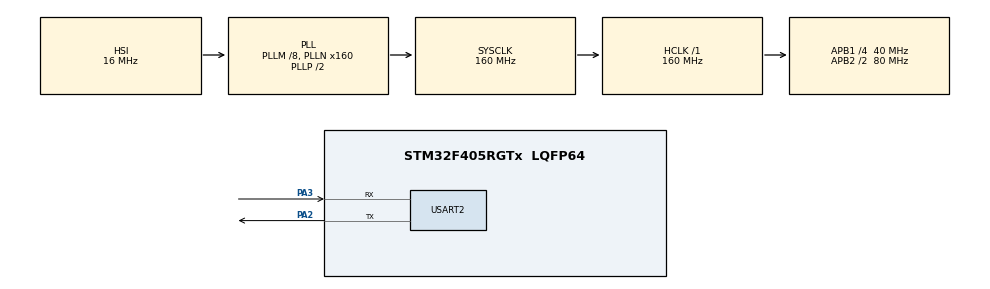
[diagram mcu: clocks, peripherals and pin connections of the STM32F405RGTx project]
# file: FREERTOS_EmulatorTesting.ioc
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Mcu.Family=STM32F4
Mcu.Name=STM32F405RGTx
Mcu.Package=LQFP64
NVIC.PriorityGroup=NVIC_PRIORITYGROUP_4
NVIC.TIM4_IRQn=true\:15\:0\:false\:false\:true\:false\:true\:true
NVIC.TimeBase=TIM4_IRQn
NVIC.TimeBaseIP=TIM4
NVIC.USART2_IRQn=true\:0\:0\:false\:false\:true\:true\:true\:true
PA13.Mode=Serial_Wire
PA13.Signal=SYS_JTMS-SWDIO
PA14.Mode=Serial_Wire
PA14.Signal=SYS_JTCK-SWCLK
PA2.Mode=Asynchronous
PA2.Signal=USART2_TX
PA3.Mode=Asynchronous
PA3.Signal=USART2_RX
ProjectManager.HeapSize=0x200
ProjectManager.StackSize=0x400
ProjectManager.TargetToolchain=STM32CubeIDE
RCC.48MHZClocksFreq_Value=80000000
RCC.AHBFreq_Value=160000000
RCC.APB1CLKDivider=RCC_HCLK_DIV4
RCC.APB1Freq_Value=40000000
RCC.APB1TimFreq_Value=80000000
RCC.APB2CLKDivider=RCC_HCLK_DIV2
RCC.APB2Freq_Value=80000000
RCC.APB2TimFreq_Value=160000000
RCC.CortexFreq_Value=160000000
RCC.HCLKFreq_Value=160000000
RCC.HSE_VALUE=25000000
RCC.HSI_VALUE=16000000
RCC.LSE_VALUE=32768
RCC.PLLM=8
RCC.PLLN=160
RCC.SYSCLKFreq_VALUE=160000000
RCC.SYSCLKSource=RCC_SYSCLKSOURCE_PLLCLK
RCC.VCOOutputFreq_Value=320000000
USART2.VirtualMode=VM_ASYNC
VP_SYS_VS_tim4.Mode=TIM4
board=custom

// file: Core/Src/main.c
/* USER CODE BEGIN Header */
/**
  ******************************************************************************
  * @file           : main.c
  * @brief          : Main program body
  ******************************************************************************
  * @attention
  *
  * Copyright (c) 2024 STMicroelectronics.
  * All rights reserved.
  *
  * This software is licensed under terms that can be found in the LICENSE file
  * in the root directory of this software component.
  * If no LICENSE file comes with this software, it is provided AS-IS.
  *
  ******************************************************************************
  */
/* USER CODE END Header */
#include "main.h"

/* USER CODE BEGIN Includes */
#include <stdio.h>
#include <string.h>
#include <stdint.h>
#include "FreeRTOS.h"
#include "task.h"
/* USER CODE END Includes */

/* USER CODE BEGIN PTD */
#define USE_USART_DEBUG

/* USER CODE END PTD */

UART_HandleTypeDef huart2;

/* USER CODE BEGIN PV */
BaseType_t status;
TaskHandle_t xTaskHandler1 = NULL;
TaskHandle_t xTaskHandler2 = NULL;
#define DWT_CTRL (*(volatile uint32_t * ) 0xE0001000)
/* USER CODE END PV */

void SystemClock_Config(void);
static void MX_GPIO_Init(void);
static void MX_USART2_UART_Init(void);
/* USER CODE BEGIN PFP */
static void task1_handler(void * Parameter);
static void task2_handler(void * Parameter);
/* USER CODE END PFP */

/* USER CODE BEGIN 0 */
void vTask1_Handler(void *);
void vTask2_Handler(void *);
char msg[50];

/* USER CODE END 0 */

int main(void)
{
  /* USER CODE BEGIN 1 */
   DWT_CTRL |= (1<<0);

  /* USER CODE END 1 */

  /* MCU Configuration--------------------------------------------------------*/

  /* Reset of all peripherals, Initializes the Flash interface and the Systick. */
  HAL_Init();

  /* Configure the system clock */
  SystemClock_Config();

  /* Initialize all configured peripherals */
  MX_GPIO_Init();
  MX_USART2_UART_Init();
  /* USER CODE BEGIN 2 */
  SEGGER_SYSVIEW_Conf();
  SEGGER_SYSVIEW_Start();

  HAL_UART_Transmit(&huart2,"RTOS\r\n",6,HAL_MAX_DELAY);
  /*Create Two Tasks */
  xTaskCreate(vTask1_Handler,"Task-1",configMINIMAL_STACK_SIZE,NULL,2,&xTaskHandler1);
  xTaskCreate(vTask2_Handler,"Task-2",configMINIMAL_STACK_SIZE,NULL,2,&xTaskHandler2);

  /*Start Scheduler */
  vTaskStartScheduler();
  /* USER CODE END 2 */

  /* Infinite loop */
  while (1)
  {

  }
}

void vTask1_Handler(void *pvParameters)
{
	while(1)
	{
		HAL_UART_Transmit(&huart2,"Hello world from task-1\r\n", 27,HAL_MAX_DELAY);
		taskYIELD();
	}
}

void vTask2_Handler(void *pvParameter)
{
	while(1)
	{
		HAL_UART_Transmit(&huart2,"Hello world from task-2\r\n",27,HAL_MAX_DELAY);
		taskYIELD();
	}
}
void SystemClock_Config(void)
{
  RCC_OscInitTypeDef RCC_OscInitStruct = {0};
  RCC_ClkInitTypeDef RCC_ClkInitStruct = {0};

  /** Configure the main internal regulator output voltage
  */
  __HAL_RCC_PWR_CLK_ENABLE();
  __HAL_PWR_VOLTAGESCALING_CONFIG(PWR_REGULATOR_VOLTAGE_SCALE1);

  /** Initializes the RCC Oscillators according to the specified parameters
  * in the RCC_OscInitTypeDef structure.
  */
  RCC_OscInitStruct.OscillatorType = RCC_OSCILLATORTYPE_HSI;
  RCC_OscInitStruct.HSIState = RCC_HSI_ON;
  RCC_OscInitStruct.HSICalibrationValue = RCC_HSICALIBRATION_DEFAULT;
  RCC_OscInitStruct.PLL.PLLState = RCC_PLL_ON;
  RCC_OscInitStruct.PLL.PLLSource = RCC_PLLSOURCE_HSI;
  RCC_OscInitStruct.PLL.PLLM = 8;
  RCC_OscInitStruct.PLL.PLLN = 160;
  RCC_OscInitStruct.PLL.PLLP = RCC_PLLP_DIV2;
  RCC_OscInitStruct.PLL.PLLQ = 4;
  if (HAL_RCC_OscConfig(&RCC_OscInitStruct) != HAL_OK)
  {
    Error_Handler();
  }

  /** Initializes the CPU, AHB and APB buses clocks
  */
  RCC_ClkInitStruct.ClockType = RCC_CLOCKTYPE_HCLK|RCC_CLOCKTYPE_SYSCLK
                              |RCC_CLOCKTYPE_PCLK1|RCC_CLOCKTYPE_PCLK2;
  RCC_ClkInitStruct.SYSCLKSource = RCC_SYSCLKSOURCE_PLLCLK;
  RCC_ClkInitStruct.AHBCLKDivider = RCC_SYSCLK_DIV1;
  RCC_ClkInitStruct.APB1CLKDivider = RCC_HCLK_DIV4;
  RCC_ClkInitStruct.APB2CLKDivider = RCC_HCLK_DIV2;

  if (HAL_RCC_ClockConfig(&RCC_ClkInitStruct, FLASH_LATENCY_5) != HAL_OK)
  {
    Error_Handler();
  }
}

static void MX_USART2_UART_Init(void)
{

  huart2.Instance = USART2;
  huart2.Init.BaudRate = 115200;
  huart2.Init.WordLength = UART_WORDLENGTH_8B;
  huart2.Init.StopBits = UART_STOPBITS_1;
  huart2.Init.Parity = UART_PARITY_NONE;
  huart2.Init.Mode = UART_MODE_TX_RX;
  huart2.Init.HwFlowCtl = UART_HWCONTROL_NONE;
  huart2.Init.OverSampling = UART_OVERSAMPLING_16;
  if (HAL_UART_Init(&huart2) != HAL_OK)
  {
    Error_Handler();
  }

}

static void MX_GPIO_Init(void)
{

  /* GPIO Ports Clock Enable */
  __HAL_RCC_GPIOA_CLK_ENABLE();

}

void HAL_TIM_PeriodElapsedCallback(TIM_HandleTypeDef *htim)
{
  if (htim->Instance == TIM4) {
    HAL_IncTick();
  }
}

void Error_Handler(void)
{
  __disable_irq();
  while (1)
  {
  }
}
